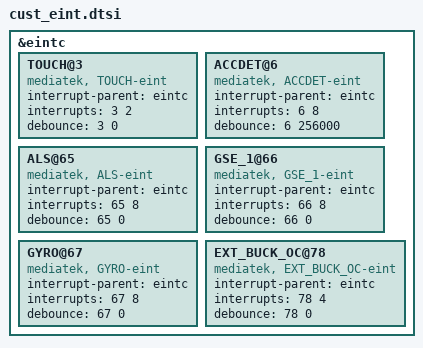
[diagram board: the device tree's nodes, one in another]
/*
 * Generated by MTK SP DrvGen Version 03.13.6 for MT6753. Copyright MediaTek Inc. (C) 2013.
 * Fri Jan 06 10:43:18 2017
 * Do Not Modify the File.
 */

/*************************
 * EINT DTSI File
*************************/

&eintc {
	TOUCH@3 {
		compatible = "mediatek, TOUCH-eint";
		interrupt-parent = <&eintc>;
		interrupts = <3 2>;
		debounce = <3 0>;
	};

	ACCDET@6 {
		compatible = "mediatek, ACCDET-eint";
		interrupt-parent = <&eintc>;
		interrupts = <6 8>;
		debounce = <6 256000>;
	};

	ALS@65 {
		compatible = "mediatek, ALS-eint";
		interrupt-parent = <&eintc>;
		interrupts = <65 8>;
		debounce = <65 0>;
	};

	GSE_1@66 {
		compatible = "mediatek, GSE_1-eint";
		interrupt-parent = <&eintc>;
		interrupts = <66 8>;
		debounce = <66 0>;
	};

	GYRO@67 {
		compatible = "mediatek, GYRO-eint";
		interrupt-parent = <&eintc>;
		interrupts = <67 8>;
		debounce = <67 0>;
	};

	EXT_BUCK_OC@78 {
		compatible = "mediatek, EXT_BUCK_OC-eint";
		interrupt-parent = <&eintc>;
		interrupts = <78 4>;
		debounce = <78 0>;
	};

};
